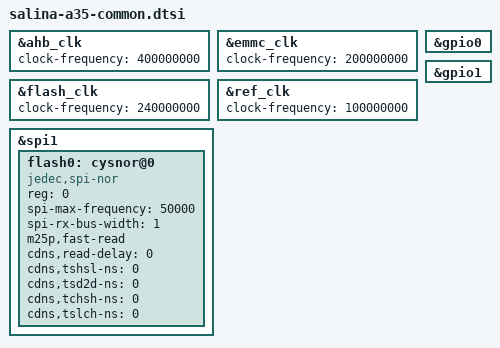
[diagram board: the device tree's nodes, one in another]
// SPDX-License-Identifier: (GPL-2.0-only or BSD-2-Clause)
/*
 * Copyright 2023-2024 Advanced Micro Devices, Inc.
 */

&ahb_clk {
	clock-frequency = <400000000>;
};

&emmc_clk {
	clock-frequency = <200000000>;
};

&flash_clk {
	clock-frequency = <240000000>;
};

&ref_clk {
	clock-frequency = <100000000>;
};

&gpio0 {
	status = "ok";
};

&gpio1 {
	status = "ok";
};

&spi1 {
	status = "okay";

	flash0: cysnor@0 {
		compatible = "jedec,spi-nor";
		reg = <0>;
		spi-max-frequency = <50000>;
		spi-rx-bus-width = <1>;
		m25p,fast-read;
		cdns,read-delay = <0>;
		cdns,tshsl-ns = <0>;
		cdns,tsd2d-ns = <0>;
		cdns,tchsh-ns = <0>;
		cdns,tslch-ns = <0>;
		};
};
